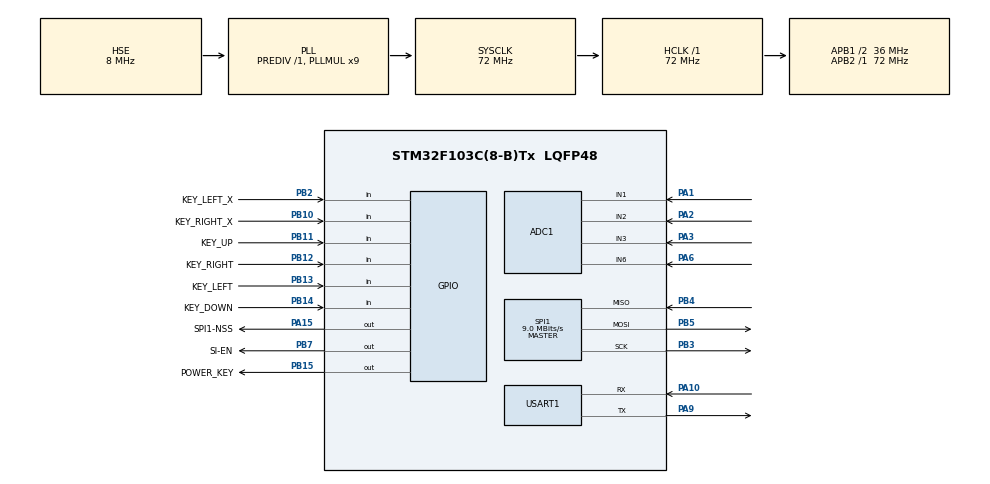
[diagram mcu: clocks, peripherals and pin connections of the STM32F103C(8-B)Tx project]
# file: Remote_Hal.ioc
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ADC1.Channel-0\#ChannelRegularConversion=ADC_CHANNEL_1
ADC1.Channel-1\#ChannelRegularConversion=ADC_CHANNEL_6
ADC1.Channel-2\#ChannelRegularConversion=ADC_CHANNEL_2
ADC1.Channel-4\#ChannelRegularConversion=ADC_CHANNEL_3
ADC1.ContinuousConvMode=ENABLE
ADC1.NbrOfConversion=4
ADC1.NbrOfConversionFlag=1
ADC1.Rank-0\#ChannelRegularConversion=1
ADC1.Rank-1\#ChannelRegularConversion=2
ADC1.Rank-2\#ChannelRegularConversion=3
ADC1.Rank-4\#ChannelRegularConversion=4
ADC1.SamplingTime-0\#ChannelRegularConversion=ADC_SAMPLETIME_13CYCLES_5
ADC1.SamplingTime-1\#ChannelRegularConversion=ADC_SAMPLETIME_13CYCLES_5
ADC1.SamplingTime-2\#ChannelRegularConversion=ADC_SAMPLETIME_13CYCLES_5
ADC1.SamplingTime-4\#ChannelRegularConversion=ADC_SAMPLETIME_13CYCLES_5
ADC1.master=1
Dma.ADC1.0.Direction=DMA_PERIPH_TO_MEMORY
Dma.ADC1.0.Instance=DMA1_Channel1
Dma.ADC1.0.MemDataAlignment=DMA_MDATAALIGN_HALFWORD
Dma.ADC1.0.MemInc=DMA_MINC_ENABLE
Dma.ADC1.0.Mode=DMA_CIRCULAR
Dma.ADC1.0.PeriphDataAlignment=DMA_PDATAALIGN_HALFWORD
Dma.ADC1.0.PeriphInc=DMA_PINC_DISABLE
Dma.ADC1.0.Priority=DMA_PRIORITY_LOW
Dma.Request0=ADC1
Mcu.Family=STM32F1
Mcu.Name=STM32F103C(8-B)Tx
Mcu.Package=LQFP48
NVIC.DMA1_Channel1_IRQn=true\:0\:0\:false\:false\:true\:false\:true\:true
NVIC.PriorityGroup=NVIC_PRIORITYGROUP_4
PA1.Signal=ADCx_IN1
PA10.Mode=Asynchronous
PA10.Signal=USART1_RX
PA13.Mode=Serial_Wire
PA13.Signal=SYS_JTMS-SWDIO
PA14.Mode=Serial_Wire
PA14.Signal=SYS_JTCK-SWCLK
PA15.GPIO_Label=SPI1-NSS
PA15.PinState=GPIO_PIN_SET
PA15.Signal=GPIO_Output
PA2.Signal=ADCx_IN2
PA3.Signal=ADCx_IN3
PA6.Signal=ADCx_IN6
PA9.Mode=Asynchronous
PA9.Signal=USART1_TX
PB10.GPIO_Label=KEY_RIGHT_X
PB10.GPIO_PuPd=GPIO_PULLUP
PB10.Signal=GPIO_Input
PB11.GPIO_Label=KEY_UP
PB11.GPIO_PuPd=GPIO_PULLUP
PB11.Signal=GPIO_Input
PB12.GPIO_Label=KEY_RIGHT
PB12.GPIO_PuPd=GPIO_PULLUP
PB12.Signal=GPIO_Input
PB13.GPIO_Label=KEY_LEFT
PB13.GPIO_PuPd=GPIO_PULLUP
PB13.Signal=GPIO_Input
PB14.GPIO_Label=KEY_DOWN
PB14.GPIO_PuPd=GPIO_PULLUP
PB14.Signal=GPIO_Input
PB15.GPIO_Label=POWER_KEY
PB15.PinState=GPIO_PIN_SET
PB15.Signal=GPIO_Output
PB2.GPIO_Label=KEY_LEFT_X
PB2.GPIO_PuPd=GPIO_PULLUP
PB2.Signal=GPIO_Input
PB3.Mode=Full_Duplex_Master
PB3.Signal=SPI1_SCK
PB4.Mode=Full_Duplex_Master
PB4.Signal=SPI1_MISO
PB5.Mode=Full_Duplex_Master
PB5.Signal=SPI1_MOSI
PB7.GPIO_Label=SI-EN
PB7.Signal=GPIO_Output
PC14-OSC32_IN.Mode=LSE-External-Oscillator
PC14-OSC32_IN.Signal=RCC_OSC32_IN
PC15-OSC32_OUT.Mode=LSE-External-Oscillator
PC15-OSC32_OUT.Signal=RCC_OSC32_OUT
PD0-OSC_IN.Mode=HSE-External-Oscillator
PD0-OSC_IN.Signal=RCC_OSC_IN
PD1-OSC_OUT.Mode=HSE-External-Oscillator
PD1-OSC_OUT.Signal=RCC_OSC_OUT
ProjectManager.HeapSize=0x200
ProjectManager.StackSize=0x400
ProjectManager.TargetToolchain=CMake
RCC.ADCPresc=RCC_ADCPCLK2_DIV6
RCC.AHBFreq_Value=72000000
RCC.APB1CLKDivider=RCC_HCLK_DIV2
RCC.APB1Freq_Value=36000000
RCC.APB1TimFreq_Value=72000000
RCC.APB2Freq_Value=72000000
RCC.APB2TimFreq_Value=72000000
RCC.HCLKFreq_Value=72000000
RCC.PLLMUL=RCC_PLL_MUL9
RCC.PLLSourceVirtual=RCC_PLLSOURCE_HSE
RCC.SYSCLKFreq_VALUE=72000000
RCC.SYSCLKSource=RCC_SYSCLKSOURCE_PLLCLK
RCC.USBFreq_Value=72000000
SH.ADCx_IN1.0=ADC1_IN1,IN1
SH.ADCx_IN2.0=ADC1_IN2,IN2
SH.ADCx_IN3.0=ADC1_IN3,IN3
SH.ADCx_IN6.0=ADC1_IN6,IN6
SPI1.BaudRatePrescaler=SPI_BAUDRATEPRESCALER_8
SPI1.CalculateBaudRate=9.0 MBits/s
SPI1.Direction=SPI_DIRECTION_2LINES
SPI1.Mode=SPI_MODE_MASTER
SPI1.VirtualType=VM_MASTER
USART1.VirtualMode=VM_ASYNC
board=custom

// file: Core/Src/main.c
/* USER CODE BEGIN Header */
/**
  ******************************************************************************
  * @file           : main.c
  * @brief          : Main program body
  ******************************************************************************
  * @attention
  *
  * Copyright (c) 2026 STMicroelectronics.
  * All rights reserved.
  *
  * This software is licensed under terms that can be found in the LICENSE file
  * in the root directory of this software component.
  * If no LICENSE file comes with this software, it is provided AS-IS.
  *
  ******************************************************************************
  */
/* USER CODE END Header */
#include "main.h"
#include "adc.h"
#include "dma.h"
#include "spi.h"
#include "usart.h"
#include "gpio.h"

/* USER CODE BEGIN Includes */
#include "common_debug.h"
#include "Application.h"
#include "Int_SI24R1.h"
/* USER CODE END Includes */

/* USER CODE BEGIN PV */
volatile TaskHandle_t g_stack_overflow_task = NULL;
volatile char *g_stack_overflow_task_name = NULL;

/* USER CODE END PV */

void SystemClock_Config(void);

int main(void)
{

  /* MCU Configuration--------------------------------------------------------*/

  /* Reset of all peripherals, Initializes the Flash interface and the Systick. */
  HAL_Init();

  /* Configure the system clock */
  SystemClock_Config();

  /* Initialize all configured peripherals */
  MX_GPIO_Init();
  MX_DMA_Init();
  MX_USART1_UART_Init();
  MX_SPI1_Init();
  MX_ADC1_Init();
  /* USER CODE BEGIN 2 */

  //完成日志输出的打印
  //HAL_UART_Transmit(&huart2, (uint8_t *)"Hello, World!\r\n", 15, HAL_MAX_DELAY);

  Int_SI24R1_Init();
  App_FreeRTOS_Start();

  /* USER CODE END 2 */

  /* Infinite loop */
  while (1)
  {

  }
}

void SystemClock_Config(void)
{
  RCC_OscInitTypeDef RCC_OscInitStruct = {0};
  RCC_ClkInitTypeDef RCC_ClkInitStruct = {0};
  RCC_PeriphCLKInitTypeDef PeriphClkInit = {0};

  /** Initializes the RCC Oscillators according to the specified parameters
  * in the RCC_OscInitTypeDef structure.
  */
  RCC_OscInitStruct.OscillatorType = RCC_OSCILLATORTYPE_HSE;
  RCC_OscInitStruct.HSEState = RCC_HSE_ON;
  RCC_OscInitStruct.HSEPredivValue = RCC_HSE_PREDIV_DIV1;
  RCC_OscInitStruct.HSIState = RCC_HSI_ON;
  RCC_OscInitStruct.PLL.PLLState = RCC_PLL_ON;
  RCC_OscInitStruct.PLL.PLLSource = RCC_PLLSOURCE_HSE;
  RCC_OscInitStruct.PLL.PLLMUL = RCC_PLL_MUL9;
  if (HAL_RCC_OscConfig(&RCC_OscInitStruct) != HAL_OK)
  {
    Error_Handler();
  }

  /** Initializes the CPU, AHB and APB buses clocks
  */
  RCC_ClkInitStruct.ClockType = RCC_CLOCKTYPE_HCLK|RCC_CLOCKTYPE_SYSCLK
                              |RCC_CLOCKTYPE_PCLK1|RCC_CLOCKTYPE_PCLK2;
  RCC_ClkInitStruct.SYSCLKSource = RCC_SYSCLKSOURCE_PLLCLK;
  RCC_ClkInitStruct.AHBCLKDivider = RCC_SYSCLK_DIV1;
  RCC_ClkInitStruct.APB1CLKDivider = RCC_HCLK_DIV2;
  RCC_ClkInitStruct.APB2CLKDivider = RCC_HCLK_DIV1;

  if (HAL_RCC_ClockConfig(&RCC_ClkInitStruct, FLASH_LATENCY_2) != HAL_OK)
  {
    Error_Handler();
  }
  PeriphClkInit.PeriphClockSelection = RCC_PERIPHCLK_ADC;
  PeriphClkInit.AdcClockSelection = RCC_ADCPCLK2_DIV6;
  if (HAL_RCCEx_PeriphCLKConfig(&PeriphClkInit) != HAL_OK)
  {
    Error_Handler();
  }
}

/* USER CODE BEGIN 4 */
/* void vApplicationStackOverflowHook(TaskHandle_t xTask, char *pcTaskName)
{
  g_stack_overflow_task = xTask;
  g_stack_overflow_task_name = pcTaskName;

  __disable_irq();
  while (1)
  {
  }
} */

/* USER CODE END 4 */

void Error_Handler(void)
{
  __disable_irq();
  while (1)
  {
  }
}
